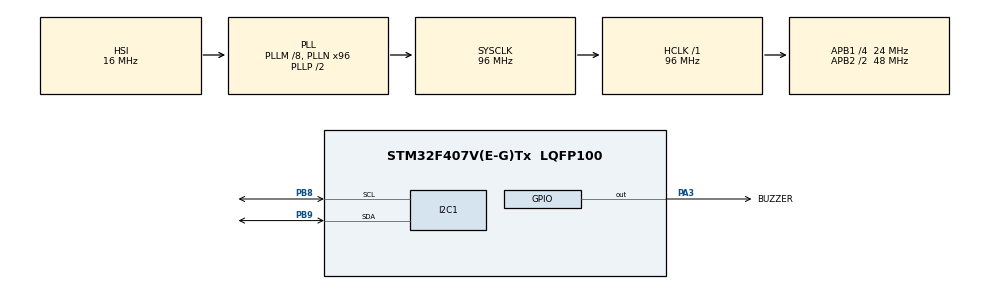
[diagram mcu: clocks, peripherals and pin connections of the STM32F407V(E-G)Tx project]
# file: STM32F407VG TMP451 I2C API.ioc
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Mcu.Family=STM32F4
Mcu.Name=STM32F407V(E-G)Tx
Mcu.Package=LQFP100
NVIC.PriorityGroup=NVIC_PRIORITYGROUP_4
PA3.GPIO_Label=BUZZER
PA3.Signal=GPIO_Output
PB8.Mode=I2C
PB8.Signal=I2C1_SCL
PB9.Mode=I2C
PB9.Signal=I2C1_SDA
ProjectManager.HeapSize=0x200
ProjectManager.StackSize=0x400
ProjectManager.TargetToolchain=STM32CubeIDE
RCC.48MHZClocksFreq_Value=48000000
RCC.AHBFreq_Value=96000000
RCC.APB1CLKDivider=RCC_HCLK_DIV4
RCC.APB1Freq_Value=24000000
RCC.APB1TimFreq_Value=48000000
RCC.APB2CLKDivider=RCC_HCLK_DIV2
RCC.APB2Freq_Value=48000000
RCC.APB2TimFreq_Value=96000000
RCC.CortexFreq_Value=96000000
RCC.HCLKFreq_Value=96000000
RCC.HSE_VALUE=25000000
RCC.HSI_VALUE=16000000
RCC.LSE_VALUE=32768
RCC.PLLM=8
RCC.PLLN=96
RCC.SYSCLKFreq_VALUE=96000000
RCC.SYSCLKSource=RCC_SYSCLKSOURCE_PLLCLK
RCC.VCOOutputFreq_Value=192000000
board=custom

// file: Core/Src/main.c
/* USER CODE BEGIN Header */
/**
 ******************************************************************************
 * @file           : main.c
 * @brief          : Main program body
 ******************************************************************************
 * @attention
 *
 * Copyright (c) 2023 STMicroelectronics.
 * All rights reserved.
 *
 * This software is licensed under terms that can be found in the LICENSE file
 * in the root directory of this software component.
 * If no LICENSE file comes with this software, it is provided AS-IS.
 *
 ******************************************************************************
 */
/* USER CODE END Header */
#include "main.h"

/* USER CODE BEGIN Includes */
#include "TMP451.h"
/* USER CODE END Includes */

I2C_HandleTypeDef hi2c1;

void SystemClock_Config(void);
static void MX_GPIO_Init(void);
static void MX_I2C1_Init(void);

/* USER CODE BEGIN 0 */

 /* TMP451 temp sensor variables */
float read_data;

/* USER CODE END 0 */

int main(void)
{

	/* MCU Configuration--------------------------------------------------------*/

	/* Reset of all peripherals, Initializes the Flash interface and the Systick. */
	HAL_Init();

	/* Configure the system clock */
	SystemClock_Config();

	/* Initialize all configured peripherals */
	MX_GPIO_Init();
	MX_I2C1_Init();
	/* USER CODE BEGIN 2 */
	if (HAL_I2C_IsDeviceReady(&hi2c1, TMP451_SLAVE_ADDRESS, 1, 10) == HAL_OK)  {
		for (uint8_t i= 30; i <35; i++) {
			HAL_GPIO_TogglePin (BUZZER_GPIO_Port, BUZZER_Pin);
			HAL_Delay(i);
			i-= 3;
		}
		HAL_GPIO_WritePin(BUZZER_GPIO_Port, BUZZER_Pin, GPIO_PIN_RESET);
	}
	else {
		Error_Handler();
	}
	TMP451_init(&hi2c1);

	/* USER CODE END 2 */

	/* Infinite loop */
	while (1)
	{

		/* USER CODE BEGIN 3 */
		read_data = TMP451_read_temp( TMP451_TEMPERATURE_LOCAL );

	}
	/* USER CODE END 3 */
}

void SystemClock_Config(void)
{
	RCC_OscInitTypeDef RCC_OscInitStruct = {0};
	RCC_ClkInitTypeDef RCC_ClkInitStruct = {0};

	/** Configure the main internal regulator output voltage
	 */
	__HAL_RCC_PWR_CLK_ENABLE();
	__HAL_PWR_VOLTAGESCALING_CONFIG(PWR_REGULATOR_VOLTAGE_SCALE1);

	/** Initializes the RCC Oscillators according to the specified parameters
	 * in the RCC_OscInitTypeDef structure.
	 */
	RCC_OscInitStruct.OscillatorType = RCC_OSCILLATORTYPE_HSI;
	RCC_OscInitStruct.HSIState = RCC_HSI_ON;
	RCC_OscInitStruct.HSICalibrationValue = RCC_HSICALIBRATION_DEFAULT;
	RCC_OscInitStruct.PLL.PLLState = RCC_PLL_ON;
	RCC_OscInitStruct.PLL.PLLSource = RCC_PLLSOURCE_HSI;
	RCC_OscInitStruct.PLL.PLLM = 8;
	RCC_OscInitStruct.PLL.PLLN = 96;
	RCC_OscInitStruct.PLL.PLLP = RCC_PLLP_DIV2;
	RCC_OscInitStruct.PLL.PLLQ = 4;
	if (HAL_RCC_OscConfig(&RCC_OscInitStruct) != HAL_OK)
	{
		Error_Handler();
	}

	/** Initializes the CPU, AHB and APB buses clocks
	 */
	RCC_ClkInitStruct.ClockType = RCC_CLOCKTYPE_HCLK|RCC_CLOCKTYPE_SYSCLK
			|RCC_CLOCKTYPE_PCLK1|RCC_CLOCKTYPE_PCLK2;
	RCC_ClkInitStruct.SYSCLKSource = RCC_SYSCLKSOURCE_PLLCLK;
	RCC_ClkInitStruct.AHBCLKDivider = RCC_SYSCLK_DIV1;
	RCC_ClkInitStruct.APB1CLKDivider = RCC_HCLK_DIV4;
	RCC_ClkInitStruct.APB2CLKDivider = RCC_HCLK_DIV2;

	if (HAL_RCC_ClockConfig(&RCC_ClkInitStruct, FLASH_LATENCY_3) != HAL_OK)
	{
		Error_Handler();
	}
}

static void MX_I2C1_Init(void)
{

	hi2c1.Instance = I2C1;
	hi2c1.Init.ClockSpeed = 100000;
	hi2c1.Init.DutyCycle = I2C_DUTYCYCLE_2;
	hi2c1.Init.OwnAddress1 = 0;
	hi2c1.Init.AddressingMode = I2C_ADDRESSINGMODE_7BIT;
	hi2c1.Init.DualAddressMode = I2C_DUALADDRESS_DISABLE;
	hi2c1.Init.OwnAddress2 = 0;
	hi2c1.Init.GeneralCallMode = I2C_GENERALCALL_DISABLE;
	hi2c1.Init.NoStretchMode = I2C_NOSTRETCH_DISABLE;
	if (HAL_I2C_Init(&hi2c1) != HAL_OK)
	{
		Error_Handler();
	}

}

static void MX_GPIO_Init(void)
{
	GPIO_InitTypeDef GPIO_InitStruct = {0};

	/* GPIO Ports Clock Enable */
	__HAL_RCC_GPIOA_CLK_ENABLE();
	__HAL_RCC_GPIOB_CLK_ENABLE();

	/*Configure GPIO pin Output Level */
	HAL_GPIO_WritePin(BUZZER_GPIO_Port, BUZZER_Pin, GPIO_PIN_RESET);

	/*Configure GPIO pin : BUZZER_Pin */
	GPIO_InitStruct.Pin = BUZZER_Pin;
	GPIO_InitStruct.Mode = GPIO_MODE_OUTPUT_PP;
	GPIO_InitStruct.Pull = GPIO_NOPULL;
	GPIO_InitStruct.Speed = GPIO_SPEED_FREQ_LOW;
	HAL_GPIO_Init(BUZZER_GPIO_Port, &GPIO_InitStruct);

}

void Error_Handler(void)
{
	/* USER CODE BEGIN Error_Handler_Debug */
	/* User can add his own implementation to report the HAL error return state */
	__disable_irq();
	while (1)
	{
		for (uint8_t i=0; i<5; i++) {
			HAL_GPIO_TogglePin (BUZZER_GPIO_Port, BUZZER_Pin);
			HAL_Delay(100);
		}
		HAL_GPIO_WritePin(BUZZER_GPIO_Port, BUZZER_Pin, GPIO_PIN_RESET);

	}
	/* USER CODE END Error_Handler_Debug */
}
